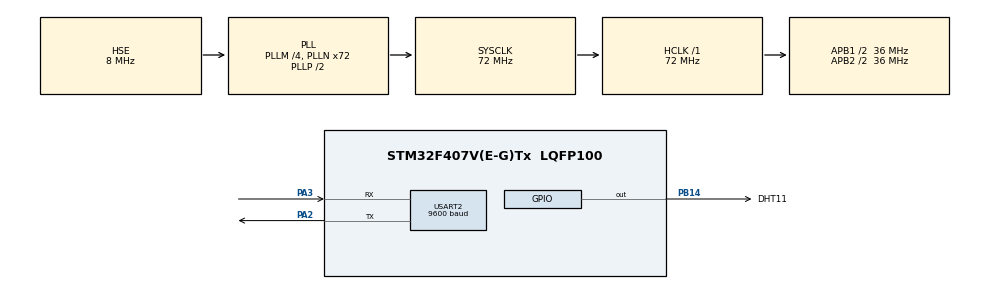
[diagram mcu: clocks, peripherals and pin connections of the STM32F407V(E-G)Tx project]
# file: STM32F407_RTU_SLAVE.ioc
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FREERTOS.Tasks01=defaultTask,24,128,StartDefaultTask,Default,NULL,Dynamic,NULL,NULL
FREERTOS.configUSE_NEWLIB_REENTRANT=1
Mcu.Family=STM32F4
Mcu.Name=STM32F407V(E-G)Tx
Mcu.Package=LQFP100
NVIC.PriorityGroup=NVIC_PRIORITYGROUP_4
NVIC.USART2_IRQn=true\:5\:0\:false\:false\:true\:true\:true\:true
PA13.Mode=Serial_Wire
PA13.Signal=SYS_JTMS-SWDIO
PA14.Mode=Serial_Wire
PA14.Signal=SYS_JTCK-SWCLK
PA2.Mode=Asynchronous
PA2.Signal=USART2_TX
PA3.Mode=Asynchronous
PA3.Signal=USART2_RX
PB14.GPIO_Label=DHT11
PB14.Signal=GPIO_Output
PC14-OSC32_IN.Mode=LSE-External-Oscillator
PC14-OSC32_IN.Signal=RCC_OSC32_IN
PC15-OSC32_OUT.Mode=LSE-External-Oscillator
PC15-OSC32_OUT.Signal=RCC_OSC32_OUT
PH0-OSC_IN.Mode=HSE-External-Oscillator
PH0-OSC_IN.Signal=RCC_OSC_IN
PH1-OSC_OUT.Mode=HSE-External-Oscillator
PH1-OSC_OUT.Signal=RCC_OSC_OUT
ProjectManager.HeapSize=0x200
ProjectManager.StackSize=0x400
ProjectManager.TargetToolchain=STM32CubeIDE
RCC.48MHZClocksFreq_Value=20571428.57142857
RCC.AHBFreq_Value=72000000
RCC.APB1CLKDivider=RCC_HCLK_DIV2
RCC.APB1Freq_Value=36000000
RCC.APB1TimFreq_Value=72000000
RCC.APB2CLKDivider=RCC_HCLK_DIV2
RCC.APB2Freq_Value=36000000
RCC.APB2TimFreq_Value=72000000
RCC.CortexFreq_Value=72000000
RCC.HCLKFreq_Value=72000000
RCC.HSE_VALUE=8000000
RCC.HSI_VALUE=16000000
RCC.PLLM=4
RCC.PLLN=72
RCC.PLLQ=7
RCC.PLLSourceVirtual=RCC_PLLSOURCE_HSE
RCC.SYSCLKFreq_VALUE=72000000
RCC.SYSCLKSource=RCC_SYSCLKSOURCE_PLLCLK
RCC.VCOOutputFreq_Value=144000000
TIM1.Period=0xffff-1
TIM1.Prescaler=72-1
TIM5.Period=0xffff-1 
TIM5.Prescaler=72-1
USART2.BaudRate=9600
USART2.VirtualMode=VM_ASYNC
VP_FREERTOS_VS_CMSIS_V2.Mode=CMSIS_V2
VP_TIM1_VS_ClockSourceINT.Mode=Internal
VP_TIM5_VS_ClockSourceINT.Mode=Internal
board=STM32F407G-DISC1

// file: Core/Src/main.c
/* USER CODE BEGIN Header */
/**
  ******************************************************************************
  * @file           : main.c
  * @brief          : Main program body
  ******************************************************************************
  * @attention
  *
  * Copyright (c) 2022 STMicroelectronics.
  * All rights reserved.
  *
  * This software is licensed under terms that can be found in the LICENSE file
  * in the root directory of this software component.
  * If no LICENSE file comes with this software, it is provided AS-IS.
  *
  ******************************************************************************
  */
/* USER CODE END Header */
#include "main.h"
#include "cmsis_os.h"

/* USER CODE BEGIN Includes */
#include "Modbus.h"
#include "dht.h"
/* USER CODE END Includes */

TIM_HandleTypeDef htim1;
TIM_HandleTypeDef htim5;

UART_HandleTypeDef huart2;

/* Definitions for defaultTask */
osThreadId_t defaultTaskHandle;
const osThreadAttr_t defaultTask_attributes = {
  .name = "defaultTask",
  .stack_size = 128 * 4,
  .priority = (osPriority_t) osPriorityNormal,
};

void SystemClock_Config(void);
static void MX_GPIO_Init(void);
static void MX_USART2_UART_Init(void);
static void MX_TIM1_Init(void);
static void MX_TIM5_Init(void);
void StartDefaultTask(void *argument);

/* USER CODE BEGIN PFP */
extern modbusHandler_t Slave_Modbus;
/* USER CODE END PFP */

/* USER CODE BEGIN 0 */
DHT_t DHT1;
uint16_t Count;
/* USER CODE END 0 */

int main(void)
{

  /* MCU Configuration--------------------------------------------------------*/

  /* Reset of all peripherals, Initializes the Flash interface and the Systick. */
  HAL_Init();

  /* Configure the system clock */
  SystemClock_Config();

  /* Initialize all configured peripherals */
  MX_GPIO_Init();
  MX_USART2_UART_Init();
  MX_TIM1_Init();
  MX_TIM5_Init();
  /* USER CODE BEGIN 2 */
  SModbus_Init();

  // ModbusH.uModbusType = MB_SLAVE;
  // ModbusH.xTypeHW = USART_HW;
  // ModbusH.port =  &huart2; // This is the UART port connected to STLINK in the NUCLEO F429
  // //ModbusH.u8id = 1; //slave ID, always different than zero
  // ModbusH.u8id = 2; //slave ID for master always 0
  // ModbusH.u16timeOut = 1000;
  // ModbusH.EN_Port = NULL; // No RS485
  //  //ModbusH2.EN_Port = LD2_GPIO_Port; // RS485 Enable
  //  //ModbusH2.EN_Pin = LD2_Pin; // RS485 Enable
  // ModbusH.u16regs = ModbusDATA;
  // ModbusH.u16regsize= sizeof(ModbusDATA)/sizeof(ModbusDATA[0]);
  //  //Initialize Modbus library
  // ModbusInit(&ModbusH);
  // //Start capturing traffic on serial Port
  // ModbusStart(&ModbusH);
  /* USER CODE END 2 */

  /* Init scheduler */
  osKernelInitialize();

  /* Create the thread(s) */
  /* creation of defaultTask */
  defaultTaskHandle = osThreadNew(StartDefaultTask, NULL, &defaultTask_attributes);

  /* Start scheduler */
  osKernelStart();

  /* We should never get here as control is now taken by the scheduler */
  /* Infinite loop */
  while (1)
  {

  }
}

void SystemClock_Config(void)
{
  RCC_OscInitTypeDef RCC_OscInitStruct = {0};
  RCC_ClkInitTypeDef RCC_ClkInitStruct = {0};

  /** Configure the main internal regulator output voltage
  */
  __HAL_RCC_PWR_CLK_ENABLE();
  __HAL_PWR_VOLTAGESCALING_CONFIG(PWR_REGULATOR_VOLTAGE_SCALE1);
  /** Initializes the RCC Oscillators according to the specified parameters
  * in the RCC_OscInitTypeDef structure.
  */
  RCC_OscInitStruct.OscillatorType = RCC_OSCILLATORTYPE_HSE;
  RCC_OscInitStruct.HSEState = RCC_HSE_ON;
  RCC_OscInitStruct.PLL.PLLState = RCC_PLL_ON;
  RCC_OscInitStruct.PLL.PLLSource = RCC_PLLSOURCE_HSE;
  RCC_OscInitStruct.PLL.PLLM = 4;
  RCC_OscInitStruct.PLL.PLLN = 72;
  RCC_OscInitStruct.PLL.PLLP = RCC_PLLP_DIV2;
  RCC_OscInitStruct.PLL.PLLQ = 7;
  if (HAL_RCC_OscConfig(&RCC_OscInitStruct) != HAL_OK)
  {
    Error_Handler();
  }
  /** Initializes the CPU, AHB and APB buses clocks
  */
  RCC_ClkInitStruct.ClockType = RCC_CLOCKTYPE_HCLK|RCC_CLOCKTYPE_SYSCLK
                              |RCC_CLOCKTYPE_PCLK1|RCC_CLOCKTYPE_PCLK2;
  RCC_ClkInitStruct.SYSCLKSource = RCC_SYSCLKSOURCE_PLLCLK;
  RCC_ClkInitStruct.AHBCLKDivider = RCC_SYSCLK_DIV1;
  RCC_ClkInitStruct.APB1CLKDivider = RCC_HCLK_DIV2;
  RCC_ClkInitStruct.APB2CLKDivider = RCC_HCLK_DIV2;

  if (HAL_RCC_ClockConfig(&RCC_ClkInitStruct, FLASH_LATENCY_2) != HAL_OK)
  {
    Error_Handler();
  }
}

static void MX_TIM1_Init(void)
{

  TIM_ClockConfigTypeDef sClockSourceConfig = {0};
  TIM_MasterConfigTypeDef sMasterConfig = {0};

  htim1.Instance = TIM1;
  htim1.Init.Prescaler = 72-1;
  htim1.Init.CounterMode = TIM_COUNTERMODE_UP;
  htim1.Init.Period = 0xffff-1;
  htim1.Init.ClockDivision = TIM_CLOCKDIVISION_DIV1;
  htim1.Init.RepetitionCounter = 0;
  htim1.Init.AutoReloadPreload = TIM_AUTORELOAD_PRELOAD_DISABLE;
  if (HAL_TIM_Base_Init(&htim1) != HAL_OK)
  {
    Error_Handler();
  }
  sClockSourceConfig.ClockSource = TIM_CLOCKSOURCE_INTERNAL;
  if (HAL_TIM_ConfigClockSource(&htim1, &sClockSourceConfig) != HAL_OK)
  {
    Error_Handler();
  }
  sMasterConfig.MasterOutputTrigger = TIM_TRGO_RESET;
  sMasterConfig.MasterSlaveMode = TIM_MASTERSLAVEMODE_DISABLE;
  if (HAL_TIMEx_MasterConfigSynchronization(&htim1, &sMasterConfig) != HAL_OK)
  {
    Error_Handler();
  }

}

static void MX_TIM5_Init(void)
{

  TIM_ClockConfigTypeDef sClockSourceConfig = {0};
  TIM_MasterConfigTypeDef sMasterConfig = {0};

  htim5.Instance = TIM5;
  htim5.Init.Prescaler = 72-1;
  htim5.Init.CounterMode = TIM_COUNTERMODE_UP;
  htim5.Init.Period = 0xffff-1 ;
  htim5.Init.ClockDivision = TIM_CLOCKDIVISION_DIV1;
  htim5.Init.AutoReloadPreload = TIM_AUTORELOAD_PRELOAD_DISABLE;
  if (HAL_TIM_Base_Init(&htim5) != HAL_OK)
  {
    Error_Handler();
  }
  sClockSourceConfig.ClockSource = TIM_CLOCKSOURCE_INTERNAL;
  if (HAL_TIM_ConfigClockSource(&htim5, &sClockSourceConfig) != HAL_OK)
  {
    Error_Handler();
  }
  sMasterConfig.MasterOutputTrigger = TIM_TRGO_RESET;
  sMasterConfig.MasterSlaveMode = TIM_MASTERSLAVEMODE_DISABLE;
  if (HAL_TIMEx_MasterConfigSynchronization(&htim5, &sMasterConfig) != HAL_OK)
  {
    Error_Handler();
  }

}

static void MX_USART2_UART_Init(void)
{

  huart2.Instance = USART2;
  huart2.Init.BaudRate = 9600;
  huart2.Init.WordLength = UART_WORDLENGTH_8B;
  huart2.Init.StopBits = UART_STOPBITS_1;
  huart2.Init.Parity = UART_PARITY_NONE;
  huart2.Init.Mode = UART_MODE_TX_RX;
  huart2.Init.HwFlowCtl = UART_HWCONTROL_NONE;
  huart2.Init.OverSampling = UART_OVERSAMPLING_16;
  if (HAL_UART_Init(&huart2) != HAL_OK)
  {
    Error_Handler();
  }

}

static void MX_GPIO_Init(void)
{
  GPIO_InitTypeDef GPIO_InitStruct = {0};

  /* GPIO Ports Clock Enable */
  __HAL_RCC_GPIOC_CLK_ENABLE();
  __HAL_RCC_GPIOH_CLK_ENABLE();
  __HAL_RCC_GPIOA_CLK_ENABLE();
  __HAL_RCC_GPIOB_CLK_ENABLE();

  /*Configure GPIO pin Output Level */
  HAL_GPIO_WritePin(DHT11_GPIO_Port, DHT11_Pin, GPIO_PIN_RESET);

  /*Configure GPIO pin : DHT11_Pin */
  GPIO_InitStruct.Pin = DHT11_Pin;
  GPIO_InitStruct.Mode = GPIO_MODE_OUTPUT_PP;
  GPIO_InitStruct.Pull = GPIO_NOPULL;
  GPIO_InitStruct.Speed = GPIO_SPEED_FREQ_LOW;
  HAL_GPIO_Init(DHT11_GPIO_Port, &GPIO_InitStruct);

}

void StartDefaultTask(void *argument)
{
  /* USER CODE BEGIN 5 */
	float Temp, Hump;
	osDelay(1000);
  /* Infinite loop */
  for(;;)
  {
    osDelay(1);
    osDelay(1000);
    DHT11_ReadAll(&Temp,&Hump);
    Slave_Modbus.Device->Reg[0].Value = (uint16_t)Temp;
    Slave_Modbus.Device->Reg[1].Value = (uint16_t)Hump;
  }
  /* USER CODE END 5 */
}

void Error_Handler(void)
{
  __disable_irq();
  while (1)
  {
  }
}
